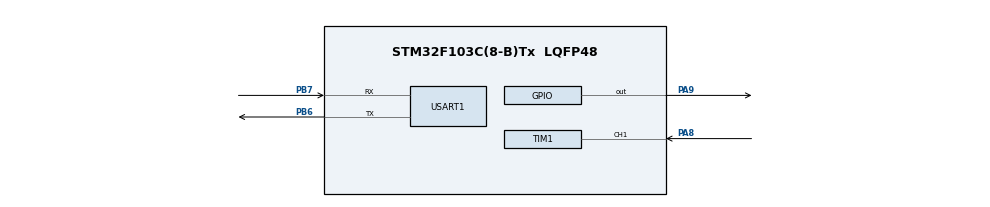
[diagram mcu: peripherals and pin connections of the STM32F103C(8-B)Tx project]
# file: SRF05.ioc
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Mcu.Family=STM32F1
ProjectManager.StackSize=0x400
PA13.Signal=SYS_JTMS-SWDIO
TIM1.Prescaler=8-1
SH.S_TIM1_CH1.0=TIM1_CH1,Input_Capture1_from_TI1
ProjectManager.TargetToolchain=MDK-ARM V5.27
PA9.Signal=GPIO_Output
PB6.Signal=USART1_TX
PB6.Mode=Asynchronous
board=custom
RCC.APB2Freq_Value=8000000
PA14.Mode=Serial_Wire
PB7.Signal=USART1_RX
PA8.Signal=S_TIM1_CH1
PA13.Mode=Serial_Wire
Mcu.Name=STM32F103C(8-B)Tx
VP_TIM1_VS_ClockSourceINT.Mode=Internal
NVIC.TIM1_CC_IRQn=true\:0\:0\:false\:false\:true\:true\:true
Mcu.Package=LQFP48
TIM1.Channel-Input_Capture1_from_TI1=TIM_CHANNEL_1
USART1.VirtualMode=VM_ASYNC
PB7.Mode=Asynchronous
PA14.Signal=SYS_JTCK-SWCLK
ProjectManager.HeapSize=0x200
NVIC.PriorityGroup=NVIC_PRIORITYGROUP_4
NVIC.USART1_IRQn=true\:0\:0\:false\:false\:true\:true\:true
RCC.APB1Freq_Value=8000000

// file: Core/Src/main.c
/* USER CODE BEGIN Header */
/**
  ******************************************************************************
  * @file           : main.c
  * @brief          : Main program body
  ******************************************************************************
  * @attention
  *
  * <h2><center>&copy; Copyright (c) 2021 STMicroelectronics.
  * All rights reserved.</center></h2>
  *
  * This software component is licensed by ST under BSD 3-Clause license,
  * the "License"; You may not use this file except in compliance with the
  * License. You may obtain a copy of the License at:
  *                        opensource.org/licenses/BSD-3-Clause
  *
  ******************************************************************************
  */
/* USER CODE END Header */
#include "main.h"

/* USER CODE BEGIN Includes */
#include "stdio.h"
#include "SR05.h"
/* USER CODE END Includes */

TIM_HandleTypeDef htim1;

UART_HandleTypeDef huart1;

/* USER CODE BEGIN PV */
char str[17];
uint8_t data;
/* USER CODE END PV */

void SystemClock_Config(void);
static void MX_GPIO_Init(void);
static void MX_TIM1_Init(void);
static void MX_USART1_UART_Init(void);

/* USER CODE BEGIN 0 */
void put_str(char *str)
{
  while(*str!=0)
  {
    HAL_UART_Transmit(&huart1,(unsigned char*)str, 1, 10);
    str++;
  }
}
/* USER CODE END 0 */

int main(void)
{

  /* MCU Configuration--------------------------------------------------------*/

  /* Reset of all peripherals, Initializes the Flash interface and the Systick. */
  HAL_Init();

  /* Configure the system clock */
  SystemClock_Config();

  /* Initialize all configured peripherals */
  MX_GPIO_Init();
  MX_TIM1_Init();
  MX_USART1_UART_Init();
  /* USER CODE BEGIN 2 */
	HAL_TIM_IC_Start_IT(&htim1, TIM_CHANNEL_1);
  /* USER CODE END 2 */

  /* Infinite loop */
  /* USER CODE BEGIN WHILE */
  while (1)
  {
		SR05_Read();
		sprintf(str,"%3d cm \n",data);
		put_str(str);
		  HAL_Delay(200);
    /* USER CODE END WHILE */

  }
}

void SystemClock_Config(void)
{
  RCC_OscInitTypeDef RCC_OscInitStruct = {0};
  RCC_ClkInitTypeDef RCC_ClkInitStruct = {0};

  /** Initializes the RCC Oscillators according to the specified parameters
  * in the RCC_OscInitTypeDef structure.
  */
  RCC_OscInitStruct.OscillatorType = RCC_OSCILLATORTYPE_HSI;
  RCC_OscInitStruct.HSIState = RCC_HSI_ON;
  RCC_OscInitStruct.HSICalibrationValue = RCC_HSICALIBRATION_DEFAULT;
  RCC_OscInitStruct.PLL.PLLState = RCC_PLL_NONE;
  if (HAL_RCC_OscConfig(&RCC_OscInitStruct) != HAL_OK)
  {
    Error_Handler();
  }
  /** Initializes the CPU, AHB and APB buses clocks
  */
  RCC_ClkInitStruct.ClockType = RCC_CLOCKTYPE_HCLK|RCC_CLOCKTYPE_SYSCLK
                              |RCC_CLOCKTYPE_PCLK1|RCC_CLOCKTYPE_PCLK2;
  RCC_ClkInitStruct.SYSCLKSource = RCC_SYSCLKSOURCE_HSI;
  RCC_ClkInitStruct.AHBCLKDivider = RCC_SYSCLK_DIV1;
  RCC_ClkInitStruct.APB1CLKDivider = RCC_HCLK_DIV1;
  RCC_ClkInitStruct.APB2CLKDivider = RCC_HCLK_DIV1;

  if (HAL_RCC_ClockConfig(&RCC_ClkInitStruct, FLASH_LATENCY_0) != HAL_OK)
  {
    Error_Handler();
  }
}

static void MX_TIM1_Init(void)
{

  TIM_ClockConfigTypeDef sClockSourceConfig = {0};
  TIM_MasterConfigTypeDef sMasterConfig = {0};
  TIM_IC_InitTypeDef sConfigIC = {0};

  htim1.Instance = TIM1;
  htim1.Init.Prescaler = 8-1;
  htim1.Init.CounterMode = TIM_COUNTERMODE_UP;
  htim1.Init.Period = 65535;
  htim1.Init.ClockDivision = TIM_CLOCKDIVISION_DIV1;
  htim1.Init.RepetitionCounter = 0;
  htim1.Init.AutoReloadPreload = TIM_AUTORELOAD_PRELOAD_DISABLE;
  if (HAL_TIM_Base_Init(&htim1) != HAL_OK)
  {
    Error_Handler();
  }
  sClockSourceConfig.ClockSource = TIM_CLOCKSOURCE_INTERNAL;
  if (HAL_TIM_ConfigClockSource(&htim1, &sClockSourceConfig) != HAL_OK)
  {
    Error_Handler();
  }
  if (HAL_TIM_IC_Init(&htim1) != HAL_OK)
  {
    Error_Handler();
  }
  sMasterConfig.MasterOutputTrigger = TIM_TRGO_RESET;
  sMasterConfig.MasterSlaveMode = TIM_MASTERSLAVEMODE_DISABLE;
  if (HAL_TIMEx_MasterConfigSynchronization(&htim1, &sMasterConfig) != HAL_OK)
  {
    Error_Handler();
  }
  sConfigIC.ICPolarity = TIM_INPUTCHANNELPOLARITY_RISING;
  sConfigIC.ICSelection = TIM_ICSELECTION_DIRECTTI;
  sConfigIC.ICPrescaler = TIM_ICPSC_DIV1;
  sConfigIC.ICFilter = 0;
  if (HAL_TIM_IC_ConfigChannel(&htim1, &sConfigIC, TIM_CHANNEL_1) != HAL_OK)
  {
    Error_Handler();
  }

}

static void MX_USART1_UART_Init(void)
{

  huart1.Instance = USART1;
  huart1.Init.BaudRate = 115200;
  huart1.Init.WordLength = UART_WORDLENGTH_8B;
  huart1.Init.StopBits = UART_STOPBITS_1;
  huart1.Init.Parity = UART_PARITY_NONE;
  huart1.Init.Mode = UART_MODE_TX_RX;
  huart1.Init.HwFlowCtl = UART_HWCONTROL_NONE;
  huart1.Init.OverSampling = UART_OVERSAMPLING_16;
  if (HAL_UART_Init(&huart1) != HAL_OK)
  {
    Error_Handler();
  }

}

static void MX_GPIO_Init(void)
{
  GPIO_InitTypeDef GPIO_InitStruct = {0};

  /* GPIO Ports Clock Enable */
  __HAL_RCC_GPIOA_CLK_ENABLE();
  __HAL_RCC_GPIOB_CLK_ENABLE();

  /*Configure GPIO pin Output Level */
  HAL_GPIO_WritePin(GPIOA, GPIO_PIN_9, GPIO_PIN_RESET);

  /*Configure GPIO pin : PA9 */
  GPIO_InitStruct.Pin = GPIO_PIN_9;
  GPIO_InitStruct.Mode = GPIO_MODE_OUTPUT_PP;
  GPIO_InitStruct.Pull = GPIO_NOPULL;
  GPIO_InitStruct.Speed = GPIO_SPEED_FREQ_LOW;
  HAL_GPIO_Init(GPIOA, &GPIO_InitStruct);

}

void Error_Handler(void)
{
  __disable_irq();
  while (1)
  {
  }
}

/************************ (C) COPYRIGHT STMicroelectronics *****END OF FILE****/
